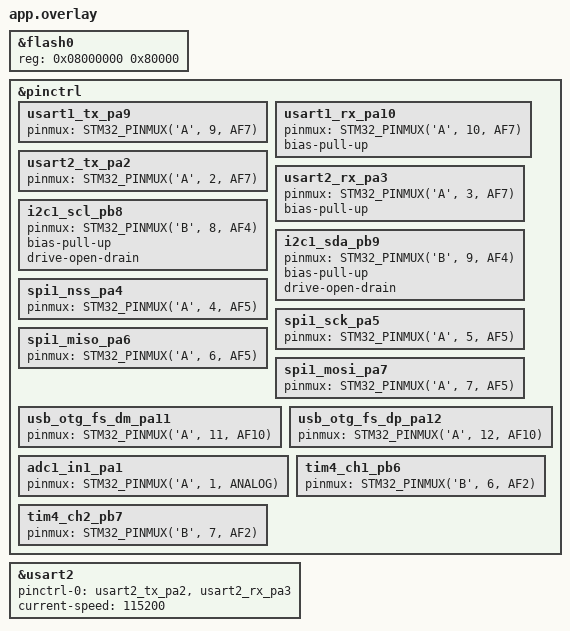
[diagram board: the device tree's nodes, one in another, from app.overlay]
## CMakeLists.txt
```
# SPDX-License-Identifier: Apache-2.0

cmake_minimum_required(VERSION 3.20.0)

find_package(Zephyr REQUIRED HINTS $ENV{ZEPHYR_BASE})
project(zephyr-recovery)

target_sources(app PRIVATE src/main.c)
```

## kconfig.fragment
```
# Empty Kconfig fragment
# Kconfig warnings are handled by patching kconfig.cmake
```

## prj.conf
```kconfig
# Zephyr RTOS Configuration for STM32F411CEU6 Recovery System

# Kernel Configuration
CONFIG_MAIN_STACK_SIZE=2048
CONFIG_HEAP_MEM_POOL_SIZE=4096

# Console and Shell
CONFIG_CONSOLE=y
CONFIG_UART_CONSOLE=y
CONFIG_SHELL=y
CONFIG_SHELL_BACKEND_SERIAL=y
CONFIG_SHELL_PROMPT_UART="recovery:~$ "

# GPIO Support
CONFIG_GPIO=y

# I2C Support
CONFIG_I2C=y

# SPI Support
CONFIG_SPI=y

# UART Support
CONFIG_SERIAL=y
CONFIG_UART_INTERRUPT_DRIVEN=y

# USB Support (optional, for USB console)
# CONFIG_USB_DEVICE_STACK=y
# CONFIG_USB_CDC_ACM=y

# Flash Support
CONFIG_FLASH=y
CONFIG_FLASH_MAP=y

# Logging
CONFIG_LOG=y
CONFIG_LOG_DEFAULT_LEVEL=3

# Debugging (optional, can be disabled for production)
CONFIG_DEBUG=y
CONFIG_DEBUG_INFO=y
```

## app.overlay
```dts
/*
 * Device tree overlay for STM32F411CEU6 Blackpill
 * Fixes missing flash reg property
 * STM32F411CE has 512KB flash (0x80000 bytes)
 * Defines pinctrl for all peripherals used by the board
 */

#include <dt-bindings/pinctrl/stm32-pinctrl.h>

&flash0 {
	reg = <0x08000000 0x80000>;
};

/* Define pinctrl nodes for all peripherals referenced in board DTS */
&pinctrl {
	/* USART1 - PA9/PA10 */
	usart1_tx_pa9: usart1_tx_pa9 {
		pinmux = <STM32_PINMUX('A', 9, AF7)>;
	};
	usart1_rx_pa10: usart1_rx_pa10 {
		pinmux = <STM32_PINMUX('A', 10, AF7)>;
		bias-pull-up;
	};
	
	/* USART2 - PA2/PA3 */
	usart2_tx_pa2: usart2_tx_pa2 {
		pinmux = <STM32_PINMUX('A', 2, AF7)>;
	};
	usart2_rx_pa3: usart2_rx_pa3 {
		pinmux = <STM32_PINMUX('A', 3, AF7)>;
		bias-pull-up;
	};
	
	/* I2C1 - PB8/PB9 */
	i2c1_scl_pb8: i2c1_scl_pb8 {
		pinmux = <STM32_PINMUX('B', 8, AF4)>;
		bias-pull-up;
		drive-open-drain;
	};
	i2c1_sda_pb9: i2c1_sda_pb9 {
		pinmux = <STM32_PINMUX('B', 9, AF4)>;
		bias-pull-up;
		drive-open-drain;
	};
	
	/* SPI1 - PA4/PA5/PA6/PA7 */
	spi1_nss_pa4: spi1_nss_pa4 {
		pinmux = <STM32_PINMUX('A', 4, AF5)>;
	};
	spi1_sck_pa5: spi1_sck_pa5 {
		pinmux = <STM32_PINMUX('A', 5, AF5)>;
	};
	spi1_miso_pa6: spi1_miso_pa6 {
		pinmux = <STM32_PINMUX('A', 6, AF5)>;
	};
	spi1_mosi_pa7: spi1_mosi_pa7 {
		pinmux = <STM32_PINMUX('A', 7, AF5)>;
	};
	
	/* USB OTG FS - PA11/PA12 */
	usb_otg_fs_dm_pa11: usb_otg_fs_dm_pa11 {
		pinmux = <STM32_PINMUX('A', 11, AF10)>;
	};
	usb_otg_fs_dp_pa12: usb_otg_fs_dp_pa12 {
		pinmux = <STM32_PINMUX('A', 12, AF10)>;
	};
	
	/* ADC1 - PA1 */
	adc1_in1_pa1: adc1_in1_pa1 {
		pinmux = <STM32_PINMUX('A', 1, ANALOG)>;
	};
	
	/* TIM4 PWM - PB6/PB7 */
	tim4_ch1_pb6: tim4_ch1_pb6 {
		pinmux = <STM32_PINMUX('B', 6, AF2)>;
	};
	tim4_ch2_pb7: tim4_ch2_pb7 {
		pinmux = <STM32_PINMUX('B', 7, AF2)>;
	};
};

/* Enable USART2 for console (PA2=TX, PA3=RX) */
&usart2 {
	pinctrl-0 = <&usart2_tx_pa2 &usart2_rx_pa3>;
	pinctrl-names = "default";
	current-speed = <115200>;
	status = "okay";
};
```

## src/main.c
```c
/*
 * STM32F411CEU6 Recovery System - Zephyr RTOS Application
 * 
 * This application provides recovery and diagnostic tools for STM32F411CEU6 (Black Pill)
 * All tools are implemented as Zephyr shell commands
 */

#include <zephyr/kernel.h>
#include <zephyr/shell/shell.h>
#include <zephyr/device.h>
#include <zephyr/drivers/gpio.h>
#include <zephyr/drivers/i2c.h>
#include <zephyr/drivers/spi.h>
#include <zephyr/drivers/uart.h>
#include <zephyr/sys/printk.h>

#define SLEEP_TIME_MS   1000

/* GPIO Commands */
static int cmd_gpio_test(const struct shell *sh, size_t argc, char **argv)
{
    shell_print(sh, "GPIO Test - Testing GPIO functionality");
    shell_print(sh, "This would test GPIO pins on STM32F411CEU6");
    shell_print(sh, "TODO: Implement actual GPIO testing logic");
    return 0;
}

static int cmd_gpio_set(const struct shell *sh, size_t argc, char **argv)
{
    if (argc < 3) {
        shell_error(sh, "Usage: gpio set <pin> <value>");
        return -1;
    }
    
    shell_print(sh, "Setting GPIO pin %s to %s", argv[1], argv[2]);
    shell_print(sh, "TODO: Implement GPIO set functionality");
    return 0;
}

static int cmd_gpio_monitor(const struct shell *sh, size_t argc, char **argv)
{
    shell_print(sh, "GPIO Monitor - Monitoring GPIO state changes");
    shell_print(sh, "TODO: Implement GPIO monitoring");
    return 0;
}

/* I2C Commands */
static int cmd_i2c_scan(const struct shell *sh, size_t argc, char **argv)
{
    shell_print(sh, "I2C Bus Scan");
    shell_print(sh, "Scanning I2C bus for devices...");
    shell_print(sh, "TODO: Implement I2C bus scanning");
    shell_print(sh, "Example: Found devices at addresses: 0x50, 0x68");
    return 0;
}

static int cmd_i2c_read(const struct shell *sh, size_t argc, char **argv)
{
    if (argc < 3) {
        shell_error(sh, "Usage: i2c read <address> <register>");
        return -1;
    }
    
    shell_print(sh, "Reading from I2C device 0x%s, register 0x%s", argv[1], argv[2]);
    shell_print(sh, "TODO: Implement I2C read functionality");
    return 0;
}

static int cmd_i2c_write(const struct shell *sh, size_t argc, char **argv)
{
    if (argc < 4) {
        shell_error(sh, "Usage: i2c write <address> <register> <value>");
        return -1;
    }
    
    shell_print(sh, "Writing 0x%s to I2C device 0x%s, register 0x%s", 
                argv[3], argv[1], argv[2]);
    shell_print(sh, "TODO: Implement I2C write functionality");
    return 0;
}

/* SPI Commands */
static int cmd_spi_test(const struct shell *sh, size_t argc, char **argv)
{
    shell_print(sh, "SPI Test - Testing SPI communication");
    shell_print(sh, "TODO: Implement SPI testing");
    return 0;
}

/* UART Commands */
static int cmd_uart_test(const struct shell *sh, size_t argc, char **argv)
{
    shell_print(sh, "UART Test - Testing UART communication");
    shell_print(sh, "TODO: Implement UART testing");
    return 0;
}

/* Flash/Memory Commands */
static int cmd_flash_program(const struct shell *sh, size_t argc, char **argv)
{
    shell_print(sh, "Flash Programming Tool");
    shell_print(sh, "TODO: Implement flash programming");
    return 0;
}

static int cmd_memory_test(const struct shell *sh, size_t argc, char **argv)
{
    shell_print(sh, "Memory Test - Testing RAM");
    shell_print(sh, "TODO: Implement memory testing");
    return 0;
}

static int cmd_system_info(const struct shell *sh, size_t argc, char **argv)
{
    shell_print(sh, "=== STM32F411CEU6 System Information ===");
    shell_print(sh, "Device: STM32F411CEU6 (Black Pill)");
    shell_print(sh, "CPU: ARM Cortex-M4 @ 100MHz");
    shell_print(sh, "Flash: 512KB");
    shell_print(sh, "RAM: 128KB");
    shell_print(sh, "Zephyr Version: %s", KERNEL_VERSION_STRING);
    return 0;
}

/* Register shell commands */
SHELL_STATIC_SUBCMD_SET_CREATE(gpio_cmds,
    SHELL_CMD(test, NULL, "Test GPIO functionality", cmd_gpio_test),
    SHELL_CMD(set, NULL, "Set GPIO pin <pin> <value>", cmd_gpio_set),
    SHELL_CMD(monitor, NULL, "Monitor GPIO state changes", cmd_gpio_monitor),
    SHELL_SUBCMD_SET_END
);

SHELL_STATIC_SUBCMD_SET_CREATE(i2c_cmds,
    SHELL_CMD(scan, NULL, "Scan I2C bus for devices", cmd_i2c_scan),
    SHELL_CMD(read, NULL, "Read from I2C device <addr> <reg>", cmd_i2c_read),
    SHELL_CMD(write, NULL, "Write to I2C device <addr> <reg> <val>", cmd_i2c_write),
    SHELL_SUBCMD_SET_END
);

SHELL_STATIC_SUBCMD_SET_CREATE(recovery_cmds,
    SHELL_CMD(flash, NULL, "Flash programming tool", cmd_flash_program),
    SHELL_CMD(memtest, NULL, "Memory test utility", cmd_memory_test),
    SHELL_CMD(sysinfo, NULL, "Display system information", cmd_system_info),
    SHELL_SUBCMD_SET_END
);

SHELL_CMD_REGISTER(gpio, &gpio_cmds, "GPIO commands", NULL);
SHELL_CMD_REGISTER(i2c, &i2c_cmds, "I2C commands", NULL);
SHELL_CMD_REGISTER(spi, NULL, "SPI test", cmd_spi_test);
SHELL_CMD_REGISTER(uart, NULL, "UART test", cmd_uart_test);
SHELL_CMD_REGISTER(recovery, &recovery_cmds, "Recovery tools", NULL);

int main(void)
{
    printk("\n");
    printk("========================================\n");
    printk("  STM32F411CEU6 Recovery System - Zephyr   \n");
    printk("========================================\n");
    printk("Type 'help' for available commands\n");
    printk("\n");

    /* Main loop - Zephyr shell handles everything */
    while (1) {
        k_msleep(SLEEP_TIME_MS);
    }

    return 0;
}
```
